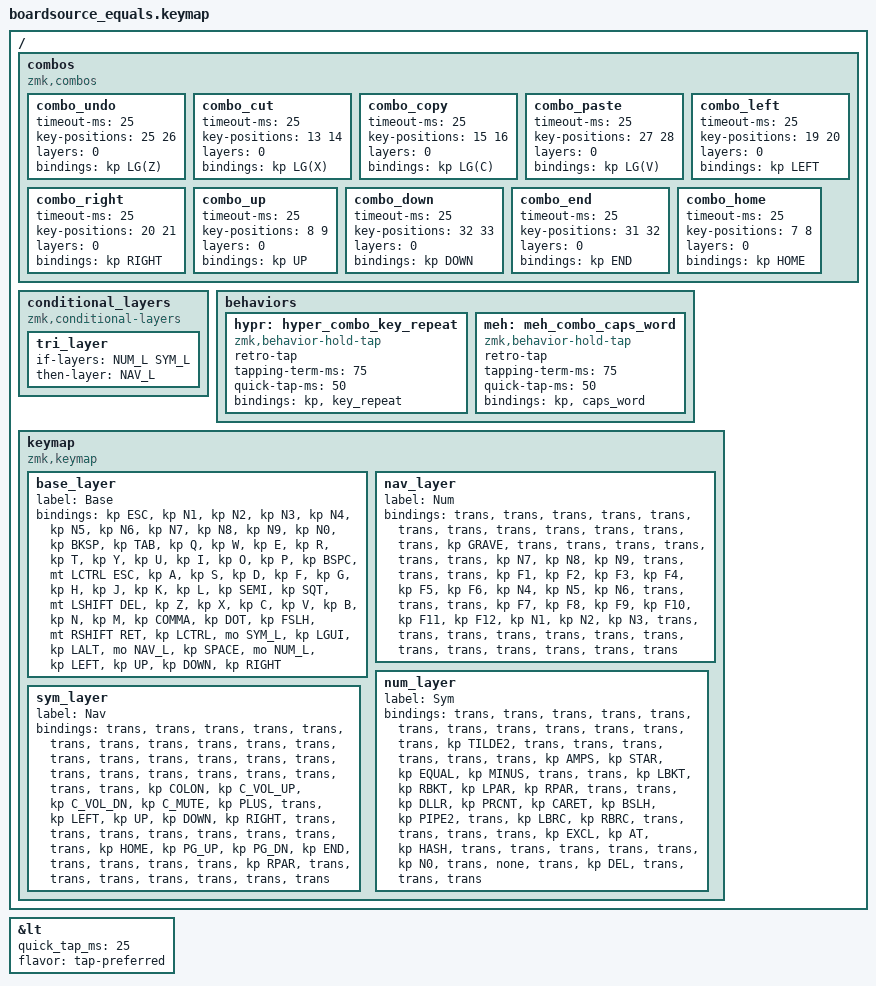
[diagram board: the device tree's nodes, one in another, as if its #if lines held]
/*
 * Copyright (c) 2022 Pete Johanson
 *
 * SPDX-License-Identifier: MIT
 */

#include <behaviors.dtsi>
#include <dt-bindings/zmk/keys.h>
#include <dt-bindings/zmk/outputs.h>

#define QWERTY_BASE 1

// #define EQUALS60 1

#define BOTTOM_ORTHO   1
// #define BOTTOM_MIT     1

#define BAS_L 0
#define NUM_L 1
#define SYM_L 2
#define NAV_L 3

// Using layer taps on thumbs, having quick tap as well helps w/ repeating space/backspace
&lt { 
	quick_tap_ms = <25>;
	flavor = "tap-preferred";
};

#define BT(n) BT_SEL n

/ {
    combos {
        compatible = "zmk,combos";
        combo_undo {
            timeout-ms = <25>;
            key-positions = <25 26>;
	    layers = <0>;
            bindings = <&kp LG(Z)>;
        };
        combo_cut {
            timeout-ms = <25>;
            key-positions = <13 14>;
	    layers = <0>;
            bindings = <&kp LG(X)>;
        };
        combo_copy {
            timeout-ms = <25>;
            key-positions = <15 16>;
	    layers = <0>;
            bindings = <&kp LG(C)>;
        };
        combo_paste {
            timeout-ms = <25>;
            key-positions = <27 28>;
	    layers = <0>;
            bindings = <&kp LG(V)>;
        };
        combo_left {
            timeout-ms = <25>;
            key-positions = <19 20>;
	    layers = <0>;
            bindings = <&kp LEFT>;
        };
        combo_right {
            timeout-ms = <25>;
            key-positions = <20 21>;
	    layers = <0>;
            bindings = <&kp RIGHT>;
        };
        combo_up {
            timeout-ms = <25>;
            key-positions = <8 9>;
	    layers = <0>;
            bindings = <&kp UP>;
        };
        combo_down {
            timeout-ms = <25>;
            key-positions = <32 33>;
	    layers = <0>;
            bindings = <&kp DOWN>;
        };
        combo_end {
            timeout-ms = <25>;
            key-positions = <31 32>;
	    layers = <0>;
            bindings = <&kp END>;
        };
        combo_home {
            timeout-ms = <25>;
            key-positions = <7 8>;
	    layers = <0>;
            bindings = <&kp HOME>;
        };
    };

    conditional_layers {
        compatible = "zmk,conditional-layers";
	tri_layer {
	    if-layers = <NUM_L SYM_L>;
	    then-layer = <NAV_L>;
	};
    };

    behaviors {
	hypr: hyper_combo_key_repeat {
	    compatible = "zmk,behavior-hold-tap";
	    #binding-cells = <2>;
	    retro-tap;
	    tapping-term-ms = <75>;
	    quick-tap-ms = <50>;
	    bindings = <&kp>, <&key_repeat>;
	};

	meh: meh_combo_caps_word {
	    compatible = "zmk,behavior-hold-tap";
	    #binding-cells = <2>;
	    retro-tap;
	    tapping-term-ms = <75>;
	    quick-tap-ms = <50>;
	    bindings = <&kp>, <&caps_word>;
	};
};

    keymap {
        compatible = "zmk,keymap";

        base_layer {
            label = "Base";
            bindings = <
#ifdef EQUALS60
 &kp ESC    &kp N1     &kp N2     &kp N3      &kp N4         &kp N5         &kp N6           &kp N7         &kp N8      &kp N9     &kp N0        &kp BKSP
#endif

#ifdef QWERTY_BASE
 &kp TAB    	 &kp Q      &kp W      &kp E       &kp R          &kp T          	&kp Y            &kp U          &kp I       &kp O      &kp P         &kp BSPC
 &mt LCTRL ESC   &kp A      &kp S      &kp D       &kp F          &kp G          	&kp H            &kp J          &kp K       &kp L      &kp SEMI      &kp SQT
 &mt LSHIFT DEL  &kp Z      &kp X      &kp C       &kp V          &kp B          	&kp N            &kp M          &kp COMMA   &kp DOT    &kp FSLH      &mt RSHIFT RET
#else
 &kp ESC    &kp Q      &kp W      &kp F       &kp P          &kp B          &kp J            &kp L          &kp U       &kp Y      &kp QUOT      &kp BKSP
 &kp TAB    &kp A      &kp R      &kp S       &kp T          &kp G          &kp M            &kp N          &kp E       &kp I      &kp O         &kp QUOT
 &mt LSHIFT DEL  &kp Z      &kp X      &kp C       &kp D          &kp V          &kp K            &kp H          &kp COMMA   &kp DOT    &kp SEMI      &kp RET
#endif
#if defined(BOTTOM_MIT)
 &kp LCTRL  &mo SYM_L   &kp LGUI  &kp LALT    &mo NAV_L          &kp SPACE                   &mo NUM_L      &kp LEFT    &kp UP     &kp DOWN      &kp RIGHT
#else
 &trans  &trans   &trans &hypr LC(LG(LA(LSHFT))) 0  &kp LCMD      &lt NUM_L SPACE      		&lt SYM_L SPACE        &kp LALT      &meh RC(RA(RSHFT)) 0  &trans     &trans      &trans
#endif
            >;
        };

        nav_layer {
            label = "Num";
            bindings = <
#ifdef EQUALS60
&trans     &trans     &trans     &trans      &trans          &trans       &trans     &trans         &trans      &trans     &trans     &trans
#endif

 &kp GRAVE	 &trans     &trans     &trans      &trans         &trans          	&trans           &kp N7      &kp N8   &kp N9    &trans      &trans
 &trans     	 &kp F1     &kp F2     &kp F3      &kp F4         &kp F5         	&kp F6           &kp N4      &kp N5   &kp N6    &trans      &trans
 &trans		 &kp F7     &kp F8     &kp F9      &kp F10        &kp F11        	&kp F12          &kp N1      &kp N2   &kp N3    &trans      &trans
#if defined(BOTTOM_MIT)
&trans  &trans        &trans     &trans      &trans                &trans             &trans      &trans   &trans &trans &trans
#else
&trans  &trans   &trans &hypr LC(LG(LA(LSHFT))) 0    &kp LCMD      &lt NUM_L SPACE      		&lt SYM_L SPACE        &kp N0      &meh RC(RA(RSHFT)) 0  &trans     &trans      &trans
#endif
            >;
        };

        num_layer {
            label = "Sym";
            bindings = <
#ifdef EQUALS60
&trans     &trans     &trans     &trans      &trans          &trans       &trans     &trans         &trans      &trans     &trans     &trans
#endif

&kp TILDE2 	 &trans     &trans     &trans       &trans         &trans          	&trans            &kp AMPS       &kp STAR    &kp EQUAL  &kp MINUS   &trans
 &trans    	 &kp LBKT   &kp RBKT   &kp LPAR     &kp RPAR       &trans          	&trans            &kp DLLR       &kp PRCNT   &kp CARET  &kp BSLH    &kp PIPE2
 &trans		 &kp LBRC   &kp RBRC   &trans       &trans         &trans          	&trans            &kp EXCL       &kp AT      &kp HASH   &trans      &trans
#if defined(BOTTOM_MIT)
&trans  &trans       &trans     &kp N0      &trans           &none            &trans        &kp DEL      &trans &trans &trans
#else
&trans  &trans   &trans  &hypr LC(LG(LA(LSHFT))) 0  &kp LCMD      &lt NUM_L SPACE      		&lt SYM_L SPACE        &kp LALT      &meh RC(RA(RSHFT)) 0   &trans     &trans      &trans
#endif
            >;
        };

        sym_layer {
            label = "Nav";
            bindings = <
#ifdef EQUALS60
&trans     &trans     &trans     &trans      &trans          &trans       &trans     &trans         &trans      &trans     &trans     &trans
#endif

&trans	   &trans        &trans       &trans        &trans         &trans	     	&trans       &trans      &trans       &trans         &trans        &trans
&trans     &kp COLON     &kp C_VOL_UP &kp C_VOL_DN  &kp C_MUTE     &kp PLUS     	&trans       &kp LEFT    &kp UP       &kp DOWN       &kp RIGHT     &trans
&trans     &trans  &trans &trans  &trans   &trans 	&trans	     &kp HOME    &kp PG_UP    &kp PG_DN      &kp END       &trans
#if defined(BOTTOM_MIT)
&trans &trans        &trans     &kp RPAR        &trans                &trans             &trans      &trans   &trans &trans &trans
#else
&bootloader  &sys_reset   &trans &hypr LC(LG(LA(LSHFT))) 0  &kp LCMD      &lt NUM_L SPACE      		&lt SYM_L SPACE        &kp LALT      &meh RC(RA(RSHFT)) 0  &trans     &trans      &trans
#endif
            >;
        };


    };
};
